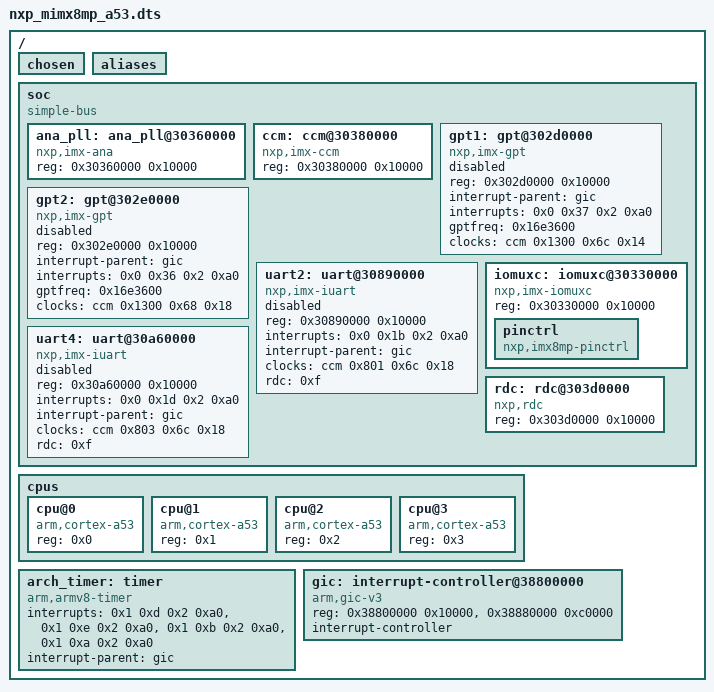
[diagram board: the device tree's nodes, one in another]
/dts-v1/;

/ {
	#address-cells = < 0x1 >;
	#size-cells = < 0x1 >;
	chosen {
	};
	aliases {
	};
	soc {
		#address-cells = < 0x1 >;
		#size-cells = < 0x1 >;
		compatible = "simple-bus";
		ranges;
		ana_pll: ana_pll@30360000 {
			compatible = "nxp,imx-ana";
			reg = < 0x30360000 0x10000 >;
		};
		ccm: ccm@30380000 {
			compatible = "nxp,imx-ccm";
			reg = < 0x30380000 0x10000 >;
			#clock-cells = < 0x3 >;
			phandle = < 0x2 >;
		};
		gpt1: gpt@302d0000 {
			compatible = "nxp,imx-gpt";
			reg = < 0x302d0000 0x10000 >;
			interrupt-parent = < &gic >;
			interrupts = < 0x0 0x37 0x2 0xa0 >;
			gptfreq = < 0x16e3600 >;
			clocks = < &ccm 0x1300 0x6c 0x14 >;
			status = "disabled";
		};
		gpt2: gpt@302e0000 {
			compatible = "nxp,imx-gpt";
			reg = < 0x302e0000 0x10000 >;
			interrupt-parent = < &gic >;
			interrupts = < 0x0 0x36 0x2 0xa0 >;
			gptfreq = < 0x16e3600 >;
			clocks = < &ccm 0x1300 0x68 0x18 >;
			status = "disabled";
		};
		uart2: uart@30890000 {
			compatible = "nxp,imx-iuart";
			reg = < 0x30890000 0x10000 >;
			interrupts = < 0x0 0x1b 0x2 0xa0 >;
			interrupt-names = "irq_0";
			interrupt-parent = < &gic >;
			clocks = < &ccm 0x801 0x6c 0x18 >;
			rdc = < 0xf >;
			status = "disabled";
		};
		uart4: uart@30a60000 {
			compatible = "nxp,imx-iuart";
			reg = < 0x30a60000 0x10000 >;
			interrupts = < 0x0 0x1d 0x2 0xa0 >;
			interrupt-names = "irq_0";
			interrupt-parent = < &gic >;
			clocks = < &ccm 0x803 0x6c 0x18 >;
			rdc = < 0xf >;
			status = "disabled";
		};
		iomuxc: iomuxc@30330000 {
			compatible = "nxp,imx-iomuxc";
			reg = < 0x30330000 0x10000 >;
			status = "okay";
			pinctrl: pinctrl {
				status = "okay";
				compatible = "nxp,imx8mp-pinctrl";
			};
		};
		rdc: rdc@303d0000 {
			compatible = "nxp,rdc";
			reg = < 0x303d0000 0x10000 >;
		};
	};
	cpus {
		#address-cells = < 0x1 >;
		#size-cells = < 0x0 >;
		cpu@0 {
			device_type = "cpu";
			compatible = "arm,cortex-a53";
			reg = < 0x0 >;
		};
		cpu@1 {
			device_type = "cpu";
			compatible = "arm,cortex-a53";
			reg = < 0x1 >;
		};
		cpu@2 {
			device_type = "cpu";
			compatible = "arm,cortex-a53";
			reg = < 0x2 >;
		};
		cpu@3 {
			device_type = "cpu";
			compatible = "arm,cortex-a53";
			reg = < 0x3 >;
		};
	};
	arch_timer: timer {
		compatible = "arm,armv8-timer";
		interrupts = < 0x1 0xd 0x2 0xa0 >, < 0x1 0xe 0x2 0xa0 >, < 0x1 0xb 0x2 0xa0 >, < 0x1 0xa 0x2 0xa0 >;
		interrupt-parent = < &gic >;
	};
	gic: interrupt-controller@38800000 {
		compatible = "arm,gic-v3", "arm,gic";
		reg = < 0x38800000 0x10000 >, < 0x38880000 0xc0000 >;
		interrupt-controller;
		#interrupt-cells = < 0x4 >;
		status = "okay";
		phandle = < 0x1 >;
	};
};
